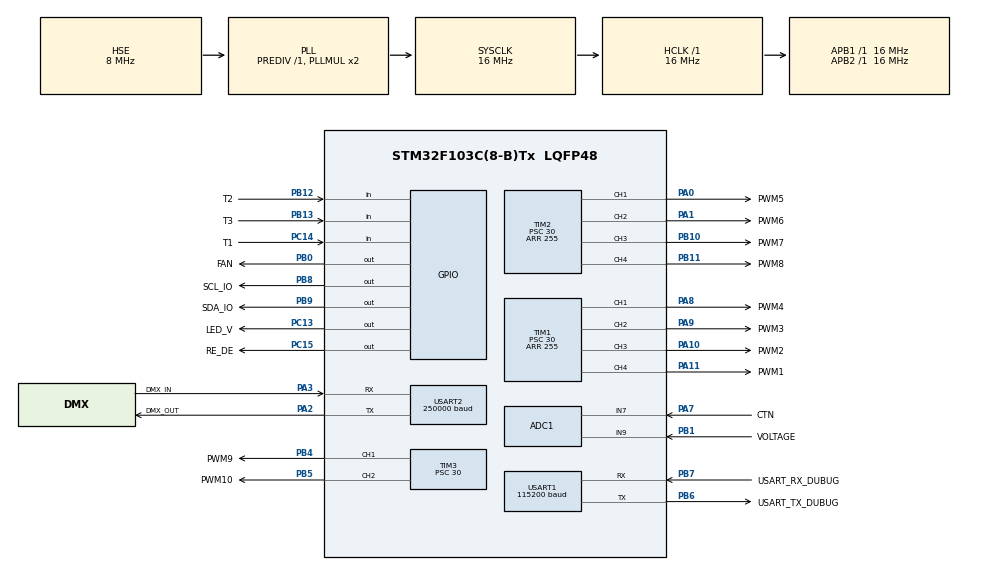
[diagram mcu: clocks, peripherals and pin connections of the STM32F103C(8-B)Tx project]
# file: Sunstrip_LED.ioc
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ADC1.Channel-0\#ChannelRegularConversion=ADC_CHANNEL_9
ADC1.NbrOfConversionFlag=1
ADC1.Rank-0\#ChannelRegularConversion=1
ADC1.SamplingTime-0\#ChannelRegularConversion=ADC_SAMPLETIME_1CYCLE_5
ADC1.master=1
Mcu.Family=STM32F1
Mcu.Name=STM32F103C(8-B)Tx
Mcu.Package=LQFP48
NVIC.PriorityGroup=NVIC_PRIORITYGROUP_4
NVIC.TIM4_IRQn=true\:2\:0\:true\:false\:true\:true\:true
NVIC.USART2_IRQn=true\:1\:0\:true\:false\:true\:true\:true
PA0-WKUP.GPIO_Label=PWM5
PA0-WKUP.Signal=S_TIM2_CH1_ETR
PA1.GPIO_Label=PWM6
PA1.Signal=S_TIM2_CH2
PA10.GPIO_Label=PWM2
PA10.Signal=S_TIM1_CH3
PA11.GPIO_Label=PWM1
PA11.Signal=S_TIM1_CH4
PA13.Mode=Serial_Wire
PA13.Signal=SYS_JTMS-SWDIO
PA14.Mode=Serial_Wire
PA14.Signal=SYS_JTCK-SWCLK
PA2.GPIO_Label=DMX_OUT
PA2.Mode=Asynchronous
PA2.Signal=USART2_TX
PA3.GPIO_Label=DMX_IN
PA3.Mode=Asynchronous
PA3.Signal=USART2_RX
PA7.GPIO_Label=CTN
PA7.Signal=ADCx_IN7
PA8.GPIO_Label=PWM4
PA8.Signal=S_TIM1_CH1
PA9.GPIO_Label=PWM3
PA9.Signal=S_TIM1_CH2
PB0.GPIO_Label=FAN
PB0.Signal=GPIO_Output
PB1.GPIO_Label=VOLTAGE
PB1.Signal=ADCx_IN9
PB10.GPIO_Label=PWM7
PB10.Signal=S_TIM2_CH3
PB11.GPIO_Label=PWM8
PB11.Signal=S_TIM2_CH4
PB12.GPIO_Label=T2
PB12.Signal=GPIO_Input
PB13.GPIO_Label=T3
PB13.Signal=GPIO_Input
PB4.GPIO_Label=PWM9
PB4.Signal=S_TIM3_CH1
PB5.GPIO_Label=PWM10
PB5.Signal=S_TIM3_CH2
PB6.GPIO_Label=USART_TX_DUBUG
PB6.Mode=Asynchronous
PB6.Signal=USART1_TX
PB7.GPIO_Label=USART_RX_DUBUG
PB7.Mode=Asynchronous
PB7.Signal=USART1_RX
PB8.GPIO_Label=SCL_IO
PB8.GPIO_ModeDefaultOutputPP=GPIO_MODE_OUTPUT_OD
PB8.PinState=GPIO_PIN_SET
PB8.Signal=GPIO_Output
PB9.GPIO_Label=SDA_IO
PB9.PinState=GPIO_PIN_SET
PB9.Signal=GPIO_Output
PC13-TAMPER-RTC.GPIO_Label=LED_V
PC13-TAMPER-RTC.Signal=GPIO_Output
PC14-OSC32_IN.GPIO_Label=T1
PC14-OSC32_IN.Signal=GPIO_Input
PC15-OSC32_OUT.GPIO_Label=RE_DE
PC15-OSC32_OUT.Signal=GPIO_Output
PD0-OSC_IN.Mode=HSE-External-Oscillator
PD0-OSC_IN.Signal=RCC_OSC_IN
PD1-OSC_OUT.Mode=HSE-External-Oscillator
PD1-OSC_OUT.Signal=RCC_OSC_OUT
ProjectManager.HeapSize=0x200
ProjectManager.StackSize=0x400
ProjectManager.TargetToolchain=STM32CubeIDE
RCC.AHBFreq_Value=16000000
RCC.APB1Freq_Value=16000000
RCC.APB1TimFreq_Value=16000000
RCC.APB2Freq_Value=16000000
RCC.APB2TimFreq_Value=16000000
RCC.HCLKFreq_Value=16000000
RCC.PLLSourceVirtual=RCC_PLLSOURCE_HSE
RCC.SYSCLKFreq_VALUE=16000000
RCC.SYSCLKSource=RCC_SYSCLKSOURCE_PLLCLK
RCC.USBFreq_Value=16000000
SH.ADCx_IN7.0=ADC1_IN7,IN7
SH.ADCx_IN9.0=ADC1_IN9,IN9
SH.S_TIM1_CH1.0=TIM1_CH1,PWM Generation1 CH1
SH.S_TIM1_CH2.0=TIM1_CH2,PWM Generation2 CH2
SH.S_TIM1_CH3.0=TIM1_CH3,PWM Generation3 CH3
SH.S_TIM1_CH4.0=TIM1_CH4,PWM Generation4 CH4
SH.S_TIM2_CH1_ETR.0=TIM2_CH1,PWM Generation1 CH1
SH.S_TIM2_CH2.0=TIM2_CH2,PWM Generation2 CH2
SH.S_TIM2_CH3.0=TIM2_CH3,PWM Generation3 CH3
SH.S_TIM2_CH4.0=TIM2_CH4,PWM Generation4 CH4
SH.S_TIM3_CH1.0=TIM3_CH1,PWM Generation1 CH1
SH.S_TIM3_CH2.0=TIM3_CH2,PWM Generation2 CH2
TIM1.Channel-PWM\ Generation1\ CH1=TIM_CHANNEL_1
TIM1.Channel-PWM\ Generation2\ CH2=TIM_CHANNEL_2
TIM1.Channel-PWM\ Generation3\ CH3=TIM_CHANNEL_3
TIM1.Channel-PWM\ Generation4\ CH4=TIM_CHANNEL_4
TIM1.OC1Preload_PWM=ENABLE
TIM1.OC2Preload_PWM=ENABLE
TIM1.Period=255
TIM1.Prescaler=30
TIM2.AutoReloadPreload=TIM_AUTORELOAD_PRELOAD_DISABLE
TIM2.Channel-PWM\ Generation1\ CH1=TIM_CHANNEL_1
TIM2.Channel-PWM\ Generation2\ CH2=TIM_CHANNEL_2
TIM2.Channel-PWM\ Generation3\ CH3=TIM_CHANNEL_3
TIM2.Channel-PWM\ Generation4\ CH4=TIM_CHANNEL_4
TIM2.Period=255
TIM2.Prescaler=30
TIM3.AutoReloadPreload=TIM_AUTORELOAD_PRELOAD_DISABLE
TIM3.Channel-PWM\ Generation1\ CH1=TIM_CHANNEL_1
TIM3.Channel-PWM\ Generation2\ CH2=TIM_CHANNEL_2
TIM3.Period=255
TIM3.Prescaler=30
TIM3.TIM_MasterOutputTrigger=TIM_TRGO_RESET
TIM4.AutoReloadPreload=TIM_AUTORELOAD_PRELOAD_ENABLE
TIM4.Period=5
TIM4.Prescaler=63000
USART1.BaudRate=115200
USART1.VirtualMode=VM_ASYNC
USART1.WordLength=WORDLENGTH_8B
USART2.BaudRate=250000
USART2.Mode=MODE_RX
USART2.StopBits=STOPBITS_2
USART2.VirtualMode=VM_ASYNC
VP_TIM1_VS_ClockSourceINT.Mode=Internal
VP_TIM2_VS_ClockSourceINT.Mode=Internal
VP_TIM3_VS_ClockSourceINT.Mode=Internal
VP_TIM4_VS_ClockSourceINT.Mode=Internal
board=custom

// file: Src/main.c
/* USER CODE BEGIN Header */
/**
  ******************************************************************************
  * @file           : main.c
  * @brief          : Main program body
  ******************************************************************************
  * @attention
  *
  * <h2><center>&copy; Copyright (c) 2019 STMicroelectronics.
  * All rights reserved.</center></h2>
  *
  * This software component is licensed by ST under BSD 3-Clause license,
  * the "License"; You may not use this file except in compliance with the
  * License. You may obtain a copy of the License at:
  *                        opensource.org/licenses/BSD-3-Clause
  *
  ******************************************************************************
  */
/* USER CODE END Header */

#include "main.h"
#include "adc.h"
#include "tim.h"
#include "usart.h"
#include "gpio.h"

/* USER CODE BEGIN Includes */
#include "App.h"
/* USER CODE END Includes */

void SystemClock_Config(void);

int main(void)
{

  /* MCU Configuration--------------------------------------------------------*/

  /* Reset of all peripherals, Initializes the Flash interface and the Systick. */
  HAL_Init();

  /* Configure the system clock */
  SystemClock_Config();

  /* Initialize all configured peripherals */
  MX_GPIO_Init();
  MX_TIM2_Init();
  MX_USART1_UART_Init();
  MX_USART2_UART_Init();
  MX_TIM3_Init();
  MX_ADC1_Init();
  MX_TIM1_Init();
  MX_TIM4_Init();
  /* USER CODE BEGIN 2 */

  DMX_uart = &huart2;

  Tick_Timer = &htim4;

  //hi2c_display = &hi2c1;

  App_Init();
  /* USER CODE END 2 */

  /* Infinite loop */
  while (1)
  {

    /* USER CODE BEGIN 3 */
	App();
  }
  /* USER CODE END 3 */
}

void SystemClock_Config(void)
{
  RCC_OscInitTypeDef RCC_OscInitStruct = {0};
  RCC_ClkInitTypeDef RCC_ClkInitStruct = {0};
  RCC_PeriphCLKInitTypeDef PeriphClkInit = {0};

  /** Initializes the CPU, AHB and APB busses clocks
  */
  RCC_OscInitStruct.OscillatorType = RCC_OSCILLATORTYPE_HSE;
  RCC_OscInitStruct.HSEState = RCC_HSE_ON;
  RCC_OscInitStruct.HSEPredivValue = RCC_HSE_PREDIV_DIV1;
  RCC_OscInitStruct.HSIState = RCC_HSI_ON;
  RCC_OscInitStruct.PLL.PLLState = RCC_PLL_ON;
  RCC_OscInitStruct.PLL.PLLSource = RCC_PLLSOURCE_HSE;
  RCC_OscInitStruct.PLL.PLLMUL = RCC_PLL_MUL2;
  if (HAL_RCC_OscConfig(&RCC_OscInitStruct) != HAL_OK)
  {
    Error_Handler();
  }
  /** Initializes the CPU, AHB and APB busses clocks
  */
  RCC_ClkInitStruct.ClockType = RCC_CLOCKTYPE_HCLK|RCC_CLOCKTYPE_SYSCLK
                              |RCC_CLOCKTYPE_PCLK1|RCC_CLOCKTYPE_PCLK2;
  RCC_ClkInitStruct.SYSCLKSource = RCC_SYSCLKSOURCE_PLLCLK;
  RCC_ClkInitStruct.AHBCLKDivider = RCC_SYSCLK_DIV1;
  RCC_ClkInitStruct.APB1CLKDivider = RCC_HCLK_DIV1;
  RCC_ClkInitStruct.APB2CLKDivider = RCC_HCLK_DIV1;

  if (HAL_RCC_ClockConfig(&RCC_ClkInitStruct, FLASH_LATENCY_0) != HAL_OK)
  {
    Error_Handler();
  }
  PeriphClkInit.PeriphClockSelection = RCC_PERIPHCLK_ADC;
  PeriphClkInit.AdcClockSelection = RCC_ADCPCLK2_DIV2;
  if (HAL_RCCEx_PeriphCLKConfig(&PeriphClkInit) != HAL_OK)
  {
    Error_Handler();
  }
}

void Error_Handler(void)
{
}

/************************ (C) COPYRIGHT STMicroelectronics *****END OF FILE****/
